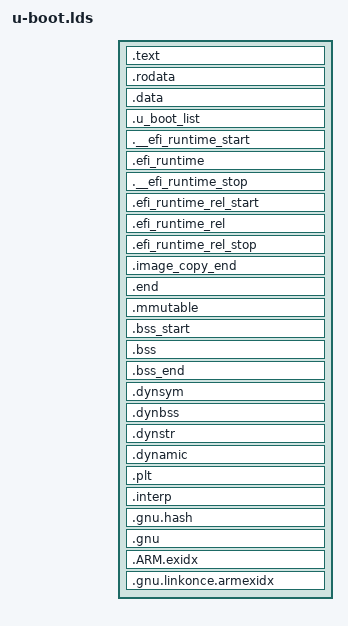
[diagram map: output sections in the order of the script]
/*
 * Copyright (c) 2004-2008 Texas Instruments
 *
 * (C) Copyright 2002
 * Gary Jennejohn, DENX Software Engineering, <garyj@denx.de>
 *
 * SPDX-License-Identifier:	GPL-2.0+
 */

#include <config.h>
#include <asm/psci.h>

OUTPUT_FORMAT("elf32-littlearm", "elf32-littlearm", "elf32-littlearm")
OUTPUT_ARCH(arm)
ENTRY(_start)
SECTIONS
{
#ifndef CONFIG_CMDLINE
	/DISCARD/ : { *(.u_boot_list_2_cmd_*) }
#endif

	. = 0x57E00000;

	. = ALIGN(4);
	.text :
	{
		*(.__image_copy_start)
		*(.vectors)
		CPUDIR/start.o (.text*)
		*(.text*)
	}



	. = ALIGN(4);
	.rodata : { *(SORT_BY_ALIGNMENT(SORT_BY_NAME(.rodata*))) }

	. = ALIGN(4);
	.data : {
		*(.data*)
	}

	. = ALIGN(4);

	. = .;

	. = ALIGN(4);
	.u_boot_list : {
		KEEP(*(SORT(.u_boot_list*)));
	}

	. = ALIGN(4);

	.__efi_runtime_start : {
		*(.__efi_runtime_start)
	}

	.efi_runtime : {
		*(efi_runtime_text)
		*(efi_runtime_data)
	}

	.__efi_runtime_stop : {
		*(.__efi_runtime_stop)
	}

	.efi_runtime_rel_start :
	{
		*(.__efi_runtime_rel_start)
	}

	.efi_runtime_rel : {
		*(.relefi_runtime_text)
		*(.relefi_runtime_data)
	}

	.efi_runtime_rel_stop :
	{
		*(.__efi_runtime_rel_stop)
	}

	. = ALIGN(4);

	.image_copy_end :
	{
		*(.__image_copy_end)
	}
	.end :
	{
		*(.__end)
	}

	_image_binary_end = .;

	/*
	 * Deprecated: this MMU section is used by pxa at present but
	 * should not be used by new boards/CPUs.
	 */
	. = ALIGN(4096);
	.mmutable : {
		*(.mmutable)
	}

/*
 * Compiler-generated __bss_start and __bss_end, see arch/arm/lib/bss.c
 * __bss_base and __bss_limit are for linker only (overlay ordering)
 */

	.bss_start __rel_dyn_start (OVERLAY) : {
		KEEP(*(.__bss_start));
		__bss_base = .;
	}

	.bss __bss_base (OVERLAY) : {
		*(.bss*)
		 . = ALIGN(4);
		 __bss_limit = .;
	}

	.bss_end __bss_limit (OVERLAY) : {
		KEEP(*(.__bss_end));
	}

	.dynsym _image_binary_end : { *(.dynsym) }
	.dynbss : { *(.dynbss) }
	.dynstr : { *(.dynstr*) }
	.dynamic : { *(.dynamic*) }
	.plt : { *(.plt*) }
	.interp : { *(.interp*) }
	.gnu.hash : { *(.gnu.hash) }
	.gnu : { *(.gnu*) }
	.ARM.exidx : { *(.ARM.exidx*) }
	.gnu.linkonce.armexidx : { *(.gnu.linkonce.armexidx.*) }
}
